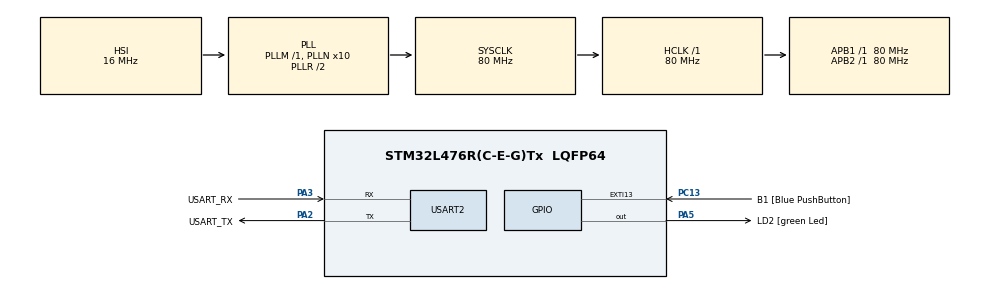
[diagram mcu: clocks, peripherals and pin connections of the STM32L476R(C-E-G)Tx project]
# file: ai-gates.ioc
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Mcu.Family=STM32L4
Mcu.Name=STM32L476R(C-E-G)Tx
Mcu.Package=LQFP64
NVIC.PriorityGroup=NVIC_PRIORITYGROUP_4
PA13\ (JTMS-SWDIO).GPIO_Label=TMS
PA13\ (JTMS-SWDIO).Mode=Serial_Wire
PA13\ (JTMS-SWDIO).Signal=SYS_JTMS-SWDIO
PA14\ (JTCK-SWCLK).GPIO_Label=TCK
PA14\ (JTCK-SWCLK).Mode=Serial_Wire
PA14\ (JTCK-SWCLK).Signal=SYS_JTCK-SWCLK
PA2.GPIO_Label=USART_TX
PA2.GPIO_Mode=GPIO_MODE_AF_PP
PA2.GPIO_PuPd=GPIO_NOPULL
PA2.GPIO_Speed=GPIO_SPEED_FREQ_VERY_HIGH
PA2.Mode=Asynchronous
PA2.Signal=USART2_TX
PA3.GPIO_Label=USART_RX
PA3.GPIO_Mode=GPIO_MODE_AF_PP
PA3.GPIO_PuPd=GPIO_NOPULL
PA3.GPIO_Speed=GPIO_SPEED_FREQ_VERY_HIGH
PA3.Mode=Asynchronous
PA3.Signal=USART2_RX
PA5.GPIO_Label=LD2 [green Led]
PA5.GPIO_ModeDefaultOutputPP=GPIO_MODE_OUTPUT_PP
PA5.GPIO_PuPd=GPIO_NOPULL
PA5.GPIO_Speed=GPIO_SPEED_FREQ_LOW
PA5.Signal=GPIO_Output
PB3\ (JTDO-TRACESWO).GPIO_Label=SWO
PB3\ (JTDO-TRACESWO).Signal=SYS_JTDO-SWO
PC13.GPIO_Label=B1 [Blue PushButton]
PC13.GPIO_ModeDefaultEXTI=GPIO_MODE_IT_FALLING
PC13.GPIO_PuPd=GPIO_NOPULL
PC13.Signal=GPXTI13
PC14-OSC32_IN\ (PC14).Mode=LSE-External-Oscillator
PC14-OSC32_IN\ (PC14).Signal=RCC_OSC32_IN
PC15-OSC32_OUT\ (PC15).Mode=LSE-External-Oscillator
PC15-OSC32_OUT\ (PC15).Signal=RCC_OSC32_OUT
PH0-OSC_IN\ (PH0).Signal=RCC_OSC_IN
PH1-OSC_OUT\ (PH1).Signal=RCC_OSC_OUT
ProjectManager.HeapSize=0x800
ProjectManager.StackSize=0x800
ProjectManager.TargetToolchain=STM32CubeIDE
RCC.ADCFreq_Value=64000000
RCC.AHBFreq_Value=80000000
RCC.APB1Freq_Value=80000000
RCC.APB1TimFreq_Value=80000000
RCC.APB2Freq_Value=80000000
RCC.APB2TimFreq_Value=80000000
RCC.CortexFreq_Value=80000000
RCC.HCLKFreq_Value=80000000
RCC.HSE_VALUE=8000000
RCC.HSI_VALUE=16000000
RCC.MSI_VALUE=4000000
RCC.PLLN=10
RCC.PLLSourceVirtual=RCC_PLLSOURCE_HSI
RCC.PREFETCH_ENABLE=1
RCC.SYSCLKFreq_VALUE=80000000
RCC.SYSCLKSource=RCC_SYSCLKSOURCE_PLLCLK
RCC.USBFreq_Value=64000000
RCC.VCOOutputFreq_Value=160000000
STMicroelectronics.X-CUBE-AI.7.3.0.ActivationBufferSizeList=1620,1620,1620,1620,1620
STMicroelectronics.X-CUBE-AI.7.3.0.ActivationBuffers=pool0;pool0;pool0;pool0;pool0
STMicroelectronics.X-CUBE-AI.7.3.0.ActivationNames=pool0
STMicroelectronics.X-CUBE-AI.7.3.0.ActivationSizes=AI_MODEL_AND_GATE_DATA_ACTIVATION_1_SIZE
STMicroelectronics.X-CUBE-AI.7.3.0.HeapSize=0x800
STMicroelectronics.X-CUBE-AI.7.3.0.InternalRamActivationBufferMaxSize=AI_MODEL_AND_GATE_DATA_ACTIVATIONS_SIZE
STMicroelectronics.X-CUBE-AI.7.3.0.LatestDirectoryUsed-060a3953240d4e9bf8e4916a821a94dc184e320e74ded668009715b26c71e694=C\:\\Users\\pas41111\\python
STMicroelectronics.X-CUBE-AI.7.3.0.LatestDirectoryUsed-206eb6122d227284f371dc1055ad900442ff0d6acad9b4016e84706fa60f2104=C\:\\Users\\pas41111\\python
STMicroelectronics.X-CUBE-AI.7.3.0.LatestDirectoryUsed-d94d1b748996a4eda8ea1467cd7f2534b248bbf0cdf2ada86f1642964ebc878a=C\:\\Users\\pas41111\\python
STMicroelectronics.X-CUBE-AI.7.3.0.LatestDirectoryUsed-ed98661261168ff6a04def1eba0c8b281f46f016ce35fb612863bb3256d85bd3=C\:\\Users\\pas41111\\python
STMicroelectronics.X-CUBE-AI.7.3.0.LatestDirectoryUsed-eeb4e9aa930aeaad72d3a5a3e96aef313594218488d33837412d1cb1a9b4d033=C\:\\Users\\pas41111\\python
STMicroelectronics.X-CUBE-AI.7.3.0.MaximumNumberOfInputLayer=1
STMicroelectronics.X-CUBE-AI.7.3.0.MaximumNumberOfOutputLayer=1
STMicroelectronics.X-CUBE-AI.7.3.0.MaximumSizeOfInputLayer=1
STMicroelectronics.X-CUBE-AI.7.3.0.MaximumSizeOfOutputLayer=1
STMicroelectronics.X-CUBE-AI.7.3.0.ModelActualCompression-060a3953240d4e9bf8e4916a821a94dc184e320e74ded668009715b26c71e694=0.0
STMicroelectronics.X-CUBE-AI.7.3.0.ModelActualCompression-206eb6122d227284f371dc1055ad900442ff0d6acad9b4016e84706fa60f2104=0.0
STMicroelectronics.X-CUBE-AI.7.3.0.ModelActualCompression-d94d1b748996a4eda8ea1467cd7f2534b248bbf0cdf2ada86f1642964ebc878a=0.0
STMicroelectronics.X-CUBE-AI.7.3.0.ModelActualCompression-ed98661261168ff6a04def1eba0c8b281f46f016ce35fb612863bb3256d85bd3=0.0
STMicroelectronics.X-CUBE-AI.7.3.0.ModelActualCompression-eeb4e9aa930aeaad72d3a5a3e96aef313594218488d33837412d1cb1a9b4d033=0.0
STMicroelectronics.X-CUBE-AI.7.3.0.ModelCompression-060a3953240d4e9bf8e4916a821a94dc184e320e74ded668009715b26c71e694=None
STMicroelectronics.X-CUBE-AI.7.3.0.ModelCompression-206eb6122d227284f371dc1055ad900442ff0d6acad9b4016e84706fa60f2104=None
STMicroelectronics.X-CUBE-AI.7.3.0.ModelCompression-d94d1b748996a4eda8ea1467cd7f2534b248bbf0cdf2ada86f1642964ebc878a=None
STMicroelectronics.X-CUBE-AI.7.3.0.ModelCompression-ed98661261168ff6a04def1eba0c8b281f46f016ce35fb612863bb3256d85bd3=None
STMicroelectronics.X-CUBE-AI.7.3.0.ModelCompression-eeb4e9aa930aeaad72d3a5a3e96aef313594218488d33837412d1cb1a9b4d033=None
STMicroelectronics.X-CUBE-AI.7.3.0.ModelFlashOccupation-060a3953240d4e9bf8e4916a821a94dc184e320e74ded668009715b26c71e694=11732
STMicroelectronics.X-CUBE-AI.7.3.0.ModelFlashOccupation-206eb6122d227284f371dc1055ad900442ff0d6acad9b4016e84706fa60f2104=11732
STMicroelectronics.X-CUBE-AI.7.3.0.ModelFlashOccupation-d94d1b748996a4eda8ea1467cd7f2534b248bbf0cdf2ada86f1642964ebc878a=11732
STMicroelectronics.X-CUBE-AI.7.3.0.ModelFlashOccupation-ed98661261168ff6a04def1eba0c8b281f46f016ce35fb612863bb3256d85bd3=11732
STMicroelectronics.X-CUBE-AI.7.3.0.ModelFlashOccupation-eeb4e9aa930aeaad72d3a5a3e96aef313594218488d33837412d1cb1a9b4d033=11732
STMicroelectronics.X-CUBE-AI.7.3.0.ModelHashList=ed98661261168ff6a04def1eba0c8b281f46f016ce35fb612863bb3256d85bd3;206eb6122d227284f371dc1055ad900442ff0d6acad9b4016e84706fa60f2104;060a3953240d4e9bf8e4916a821a94dc184e320e74ded668009715b26c71e694;d94d1b748996a4eda8ea1467cd7f2534b248bbf0cdf2ada86f1642964ebc878a;eeb4e9aa930aeaad72d3a5a3e96aef313594218488d33837412d1cb1a9b4d033
STMicroelectronics.X-CUBE-AI.7.3.0.ModelKind-060a3953240d4e9bf8e4916a821a94dc184e320e74ded668009715b26c71e694=KERAS
STMicroelectronics.X-CUBE-AI.7.3.0.ModelKind-206eb6122d227284f371dc1055ad900442ff0d6acad9b4016e84706fa60f2104=KERAS
STMicroelectronics.X-CUBE-AI.7.3.0.ModelKind-d94d1b748996a4eda8ea1467cd7f2534b248bbf0cdf2ada86f1642964ebc878a=KERAS
STMicroelectronics.X-CUBE-AI.7.3.0.ModelKind-ed98661261168ff6a04def1eba0c8b281f46f016ce35fb612863bb3256d85bd3=KERAS
STMicroelectronics.X-CUBE-AI.7.3.0.ModelKind-eeb4e9aa930aeaad72d3a5a3e96aef313594218488d33837412d1cb1a9b4d033=KERAS
STMicroelectronics.X-CUBE-AI.7.3.0.ModelMacc-060a3953240d4e9bf8e4916a821a94dc184e320e74ded668009715b26c71e694=67
STMicroelectronics.X-CUBE-AI.7.3.0.ModelMacc-206eb6122d227284f371dc1055ad900442ff0d6acad9b4016e84706fa60f2104=67
STMicroelectronics.X-CUBE-AI.7.3.0.ModelMacc-d94d1b748996a4eda8ea1467cd7f2534b248bbf0cdf2ada86f1642964ebc878a=67
STMicroelectronics.X-CUBE-AI.7.3.0.ModelMacc-ed98661261168ff6a04def1eba0c8b281f46f016ce35fb612863bb3256d85bd3=67
STMicroelectronics.X-CUBE-AI.7.3.0.ModelMacc-eeb4e9aa930aeaad72d3a5a3e96aef313594218488d33837412d1cb1a9b4d033=67
STMicroelectronics.X-CUBE-AI.7.3.0.ModelName-060a3953240d4e9bf8e4916a821a94dc184e320e74ded668009715b26c71e694=model_nor_gate
STMicroelectronics.X-CUBE-AI.7.3.0.ModelName-206eb6122d227284f371dc1055ad900442ff0d6acad9b4016e84706fa60f2104=model_or_gate
STMicroelectronics.X-CUBE-AI.7.3.0.ModelName-d94d1b748996a4eda8ea1467cd7f2534b248bbf0cdf2ada86f1642964ebc878a=model_xnor_gate
STMicroelectronics.X-CUBE-AI.7.3.0.ModelName-ed98661261168ff6a04def1eba0c8b281f46f016ce35fb612863bb3256d85bd3=model_and_gate
STMicroelectronics.X-CUBE-AI.7.3.0.ModelName-eeb4e9aa930aeaad72d3a5a3e96aef313594218488d33837412d1cb1a9b4d033=model_xor_gate
STMicroelectronics.X-CUBE-AI.7.3.0.ModelNameList=model_and_gate,model_or_gate,model_nor_gate,model_xnor_gate,model_xor_gate
STMicroelectronics.X-CUBE-AI.7.3.0.ModelRamOccupation-060a3953240d4e9bf8e4916a821a94dc184e320e74ded668009715b26c71e694=1620
STMicroelectronics.X-CUBE-AI.7.3.0.ModelRamOccupation-206eb6122d227284f371dc1055ad900442ff0d6acad9b4016e84706fa60f2104=1620
STMicroelectronics.X-CUBE-AI.7.3.0.ModelRamOccupation-d94d1b748996a4eda8ea1467cd7f2534b248bbf0cdf2ada86f1642964ebc878a=1620
STMicroelectronics.X-CUBE-AI.7.3.0.ModelRamOccupation-ed98661261168ff6a04def1eba0c8b281f46f016ce35fb612863bb3256d85bd3=1620
STMicroelectronics.X-CUBE-AI.7.3.0.ModelRamOccupation-eeb4e9aa930aeaad72d3a5a3e96aef313594218488d33837412d1cb1a9b4d033=1620
STMicroelectronics.X-CUBE-AI.7.3.0.ModelStructureFile-060a3953240d4e9bf8e4916a821a94dc184e320e74ded668009715b26c71e694=C\:\\Users\\pas41111\\python\\nor-gate.h5
STMicroelectronics.X-CUBE-AI.7.3.0.ModelStructureFile-206eb6122d227284f371dc1055ad900442ff0d6acad9b4016e84706fa60f2104=C\:\\Users\\pas41111\\python\\or-gate.h5
STMicroelectronics.X-CUBE-AI.7.3.0.ModelStructureFile-d94d1b748996a4eda8ea1467cd7f2534b248bbf0cdf2ada86f1642964ebc878a=C\:\\Users\\pas41111\\python\\xnor-gate.h5
STMicroelectronics.X-CUBE-AI.7.3.0.ModelStructureFile-ed98661261168ff6a04def1eba0c8b281f46f016ce35fb612863bb3256d85bd3=C\:\\Users\\pas41111\\python\\and-gate.h5
STMicroelectronics.X-CUBE-AI.7.3.0.ModelStructureFile-eeb4e9aa930aeaad72d3a5a3e96aef313594218488d33837412d1cb1a9b4d033=C\:\\Users\\pas41111\\python\\xor-gate.h5
STMicroelectronics.X-CUBE-AI.7.3.0.ModelType-060a3953240d4e9bf8e4916a821a94dc184e320e74ded668009715b26c71e694=Saved model
STMicroelectronics.X-CUBE-AI.7.3.0.ModelType-206eb6122d227284f371dc1055ad900442ff0d6acad9b4016e84706fa60f2104=Saved model
STMicroelectronics.X-CUBE-AI.7.3.0.ModelType-d94d1b748996a4eda8ea1467cd7f2534b248bbf0cdf2ada86f1642964ebc878a=Saved model
STMicroelectronics.X-CUBE-AI.7.3.0.ModelType-ed98661261168ff6a04def1eba0c8b281f46f016ce35fb612863bb3256d85bd3=Saved model
STMicroelectronics.X-CUBE-AI.7.3.0.ModelType-eeb4e9aa930aeaad72d3a5a3e96aef313594218488d33837412d1cb1a9b4d033=Saved model
STMicroelectronics.X-CUBE-AI.7.3.0.ReadyForCodeGeneration=true
STMicroelectronics.X-CUBE-AI.7.3.0.StackSize=0x800
STMicroelectronics.X-CUBE-AI.7.3.0.WorkingBufferStartAddrList=0xFFFFFFFF,0xFFFFFFFF,0xFFFFFFFF,0xFFFFFFFF,0xFFFFFFFF
STMicroelectronics.X-CUBE-AI.7.3.0.XAaCUBEAaAICcArtificialOoIntelligenceJjCore=true
STMicroelectronics.X-CUBE-AI.7.3.0.copyWeightToRam=false
STMicroelectronics.X-CUBE-AI.7.3.0.customLayerConfigEnabled=false
STMicroelectronics.X-CUBE-AI.7.3.0.useInputAllocation=true
STMicroelectronics.X-CUBE-AI.7.3.0.useOutputAllocation=true
USART2.VirtualMode-Asynchronous=VM_ASYNC
VP_CRC_VS_CRC.Mode=CRC_Activate
VP_STMicroelectronics.X-CUBE-AI_VS_ArtificialOoIntelligenceJjXAaCUBEAaAI_7.3.0.Mode=ArtificialOoIntelligenceJjXAaCUBEAaAI
board=NUCLEO-L476RG

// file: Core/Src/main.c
/* USER CODE BEGIN Header */
/**
  ******************************************************************************
  * @file           : main.c
  * @brief          : Main program body.
  * 				  Program to test the usage of CubeAI on a STM32-L476RG as
  * 				  stand-alone application.
  * @author			: paspf
  * @date			: 2023-03-24
  * @copyright		: paspf, GNU General Public License v3.0
  ******************************************************************************
  */
/* USER CODE END Header */
#include "main.h"

/* USER CODE BEGIN Includes */
#include <stdio.h>
#include "test_gates.h"
#include "io_gate.h"
/* USER CODE END Includes */

CRC_HandleTypeDef hcrc;

UART_HandleTypeDef huart2;

void SystemClock_Config(void);
static void MX_GPIO_Init(void);
static void MX_USART2_UART_Init(void);
static void MX_CRC_Init(void);

/* USER CODE BEGIN 0 */

/**
 * @fn int _write(int, char*, int)
 * @brief Overwrite POSIX _write() function to use stdout.
 *
 * @param fd File descriptor.
 * @param ptr Output string.
 * @param len Length of Output string.
 * @return
 */
int _write(int fd, char* ptr, int len) {
    HAL_UART_Transmit(&huart2, (uint8_t *) ptr, len, HAL_MAX_DELAY);
    return len;
}

/* USER CODE END 0 */

int main(void) {

  /* MCU Configuration--------------------------------------------------------*/

  /* Reset of all peripherals, Initializes the Flash interface and the Systick. */
  HAL_Init();

  /* Configure the system clock */
  SystemClock_Config();

  /* Initialize all configured peripherals */
  MX_GPIO_Init();
  MX_USART2_UART_Init();
  MX_CRC_Init();
  /* USER CODE BEGIN 2 */
  printf("CubeAI tests...\n");
  test_gates();
  printf("Run IO Gates...\n");
  io_gates();
  /* USER CODE END 2 */

  /* Infinite loop */
  while (1)
  {

  }
}

void SystemClock_Config(void) {
  RCC_OscInitTypeDef RCC_OscInitStruct = {0};
  RCC_ClkInitTypeDef RCC_ClkInitStruct = {0};

  /**
   * Configure the main internal regulator output voltage
   */
  if (HAL_PWREx_ControlVoltageScaling(PWR_REGULATOR_VOLTAGE_SCALE1) != HAL_OK) {
    Error_Handler();
  }

  /**
   * Initializes the RCC Oscillators according to the specified parameters
   *  in the RCC_OscInitTypeDef structure.
   */
  RCC_OscInitStruct.OscillatorType = RCC_OSCILLATORTYPE_HSI;
  RCC_OscInitStruct.HSIState = RCC_HSI_ON;
  RCC_OscInitStruct.HSICalibrationValue = RCC_HSICALIBRATION_DEFAULT;
  RCC_OscInitStruct.PLL.PLLState = RCC_PLL_ON;
  RCC_OscInitStruct.PLL.PLLSource = RCC_PLLSOURCE_HSI;
  RCC_OscInitStruct.PLL.PLLM = 1;
  RCC_OscInitStruct.PLL.PLLN = 10;
  RCC_OscInitStruct.PLL.PLLP = RCC_PLLP_DIV7;
  RCC_OscInitStruct.PLL.PLLQ = RCC_PLLQ_DIV2;
  RCC_OscInitStruct.PLL.PLLR = RCC_PLLR_DIV2;
  if (HAL_RCC_OscConfig(&RCC_OscInitStruct) != HAL_OK) {
    Error_Handler();
  }

  /**
   * Initializes the CPU, AHB and APB buses clocks
   */
  RCC_ClkInitStruct.ClockType = RCC_CLOCKTYPE_HCLK|RCC_CLOCKTYPE_SYSCLK
                              |RCC_CLOCKTYPE_PCLK1|RCC_CLOCKTYPE_PCLK2;
  RCC_ClkInitStruct.SYSCLKSource = RCC_SYSCLKSOURCE_PLLCLK;
  RCC_ClkInitStruct.AHBCLKDivider = RCC_SYSCLK_DIV1;
  RCC_ClkInitStruct.APB1CLKDivider = RCC_HCLK_DIV1;
  RCC_ClkInitStruct.APB2CLKDivider = RCC_HCLK_DIV1;

  if (HAL_RCC_ClockConfig(&RCC_ClkInitStruct, FLASH_LATENCY_4) != HAL_OK) {
    Error_Handler();
  }
}

static void MX_CRC_Init(void) {

  hcrc.Instance = CRC;
  hcrc.Init.DefaultPolynomialUse = DEFAULT_POLYNOMIAL_ENABLE;
  hcrc.Init.DefaultInitValueUse = DEFAULT_INIT_VALUE_ENABLE;
  hcrc.Init.InputDataInversionMode = CRC_INPUTDATA_INVERSION_NONE;
  hcrc.Init.OutputDataInversionMode = CRC_OUTPUTDATA_INVERSION_DISABLE;
  hcrc.InputDataFormat = CRC_INPUTDATA_FORMAT_BYTES;
  if (HAL_CRC_Init(&hcrc) != HAL_OK) {
    Error_Handler();
  }

}

static void MX_USART2_UART_Init(void) {

  huart2.Instance = USART2;
  huart2.Init.BaudRate = 115200;
  huart2.Init.WordLength = UART_WORDLENGTH_8B;
  huart2.Init.StopBits = UART_STOPBITS_1;
  huart2.Init.Parity = UART_PARITY_NONE;
  huart2.Init.Mode = UART_MODE_TX_RX;
  huart2.Init.HwFlowCtl = UART_HWCONTROL_NONE;
  huart2.Init.OverSampling = UART_OVERSAMPLING_16;
  huart2.Init.OneBitSampling = UART_ONE_BIT_SAMPLE_DISABLE;
  huart2.AdvancedInit.AdvFeatureInit = UART_ADVFEATURE_NO_INIT;
  if (HAL_UART_Init(&huart2) != HAL_OK) {
    Error_Handler();
  }

}

static void MX_GPIO_Init(void) {
  GPIO_InitTypeDef GPIO_InitStruct = {0};

  /* GPIO Ports Clock Enable */
  __HAL_RCC_GPIOC_CLK_ENABLE();
  __HAL_RCC_GPIOH_CLK_ENABLE();
  __HAL_RCC_GPIOA_CLK_ENABLE();
  __HAL_RCC_GPIOB_CLK_ENABLE();

  /*Configure GPIO pin Output Level */
  HAL_GPIO_WritePin(LD2_GPIO_Port, LD2_Pin, GPIO_PIN_RESET);

  /*Configure GPIO pin : B1_Pin */
  GPIO_InitStruct.Pin = B1_Pin;
  GPIO_InitStruct.Mode = GPIO_MODE_IT_FALLING;
  GPIO_InitStruct.Pull = GPIO_NOPULL;
  HAL_GPIO_Init(B1_GPIO_Port, &GPIO_InitStruct);

  /*Configure GPIO pin : LD2_Pin */
  GPIO_InitStruct.Pin = LD2_Pin;
  GPIO_InitStruct.Mode = GPIO_MODE_OUTPUT_PP;
  GPIO_InitStruct.Pull = GPIO_NOPULL;
  GPIO_InitStruct.Speed = GPIO_SPEED_FREQ_LOW;
  HAL_GPIO_Init(LD2_GPIO_Port, &GPIO_InitStruct);

}

void Error_Handler(void) {
  __disable_irq();
  while (1)
  {
  }
}
